VERSION ""

NS_ :

BS_:

BU_: VGW

BO_ 2566844158 ET1: 8 VGW
 SG_ EngCoolantTemp : 0|8@1+ (1,-40) [-40|210] "deg" Vector__XXX

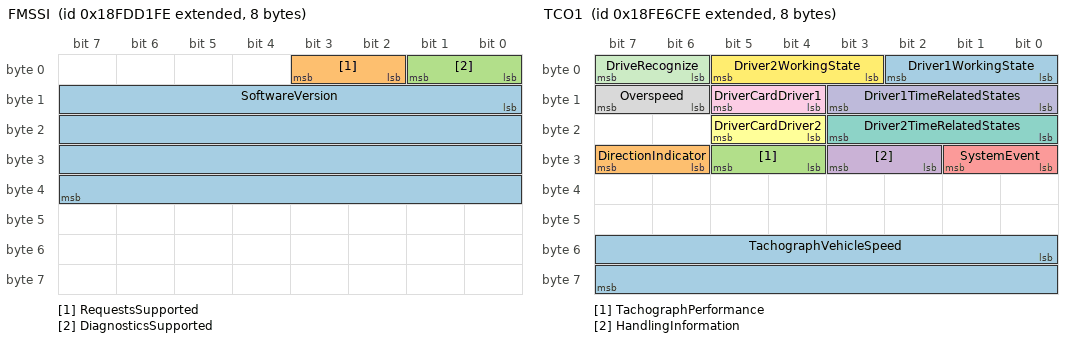
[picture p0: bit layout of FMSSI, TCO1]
BO_ 2566771198 FMSSI: 8 VGW
 SG_ SoftwareVersion : 8|32@1+ (1,0) [0|0] "" Vector__XXX
 SG_ RequestsSupported : 2|2@1+ (1,0) [0|3] "" Vector__XXX
 SG_ DiagnosticsSupported : 0|2@1+ (1,0) [0|3] "" Vector__XXX

BO_ 2566841854 HOURS: 8 VGW
 SG_ EngTotalHoursOfOperation : 0|32@1+ (0.5,0) [0|210554060.75] "hr" Vector__XXX

BO_ 2566843134 VW: 8 VGW
 SG_ AxleWeight : 8|16@1+ (0.5,0) [0|32127.5] "kg" Vector__XXX
 SG_ AxleLocation : 0|8@1+ (1,0) [0|255] "" Vector__XXX

BO_ 2566843646 VI: 255 VGW
 SG_ VehicleIdentificationNumber : 0|8@1+ (1,0) [0|255] "" Vector__XXX

BO_ 2566832638 VDHR: 8 VGW
 SG_ HghRslutionTotalVehicleDistance : 0|32@1+ (5,0) [0|21055406] "km" Vector__XXX

BO_ 2566810878 TCO1: 8 VGW
 SG_ TachographVehicleSpeed : 48|16@1+ (0.00390625,0) [0|250.996] "km/h" Vector__XXX
 SG_ DirectionIndicator : 30|2@1+ (1,0) [0|3] "" Vector__XXX
 SG_ TachographPerformance : 28|2@1+ (1,0) [0|3] "" Vector__XXX
 SG_ HandlingInformation : 26|2@1+ (1,0) [0|3] "" Vector__XXX
 SG_ SystemEvent : 24|2@1+ (1,0) [0|3] "" Vector__XXX
 SG_ DriverCardDriver2 : 20|2@1+ (1,0) [0|3] "" Vector__XXX
 SG_ Driver2TimeRelatedStates : 16|4@1+ (1,0) [0|15] "" Vector__XXX
 SG_ Overspeed : 14|2@1+ (1,0) [0|3] "" Vector__XXX
 SG_ DriverCardDriver1 : 12|2@1+ (1,0) [0|3] "" Vector__XXX
 SG_ Driver1TimeRelatedStates : 8|4@1+ (1,0) [0|15] "" Vector__XXX
 SG_ DriveRecognize : 6|2@1+ (1,0) [0|3] "" Vector__XXX
 SG_ Driver2WorkingState : 3|3@1+ (1,0) [0|7] "" Vector__XXX
 SG_ Driver1WorkingState : 0|3@1+ (1,0) [0|7] "" Vector__XXX

BO_ 2566832382 SERV: 8 VGW
 SG_ ServiceDistance : 8|16@1+ (5,-159365) [-159365|160640] "km" Vector__XXX

BO_ 2566842878 LFC: 8 VGW
 SG_ EngTotalFuelUsed : 32|32@1+ (0.5,0) [0|2105540607.5] "L" Vector__XXX

BO_ 2565866494 EEC2: 8 VGW
 SG_ AccelPedalPosition1 : 8|8@1+ (0.4,0) [0|100] "%" Vector__XXX

BO_ 2565866750 EEC1: 8 VGW
 SG_ EngSpeed : 24|16@1+ (0.125,0) [0|8031.875] "rpm" Vector__XXX

BO_ 2566847742 DD: 8 VGW
 SG_ FuelLevel : 8|8@1+ (0.4,0) [0|100] "%" Vector__XXX

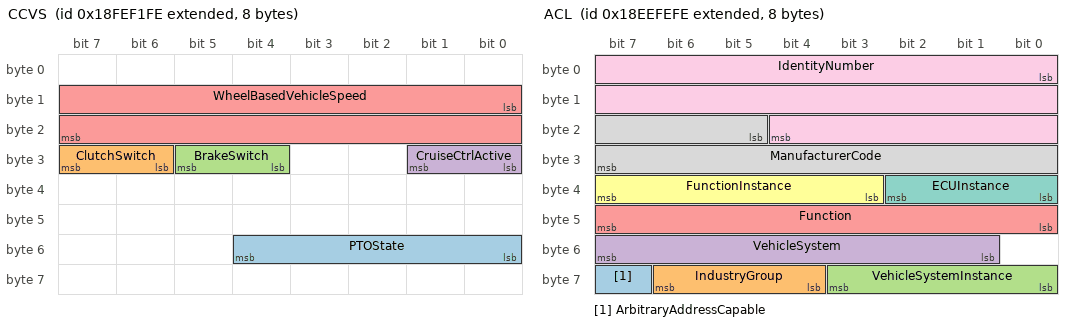
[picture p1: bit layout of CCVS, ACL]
BO_ 2566844926 CCVS: 8 VGW
 SG_ PTOState : 48|5@1+ (1,0) [0|31] "" Vector__XXX
 SG_ ClutchSwitch : 30|2@1+ (1,0) [0|3] "" Vector__XXX
 SG_ BrakeSwitch : 28|2@1+ (1,0) [0|3] "" Vector__XXX
 SG_ CruiseCtrlActive : 24|2@1+ (1,0) [0|3] "" Vector__XXX
 SG_ WheelBasedVehicleSpeed : 8|16@1+ (0.00390625,0) [0|255.99609375] "km/h" Vector__XXX

BO_ 2565799678 ACL: 8 VGW
 SG_ ArbitraryAddressCapable : 63|1@1+ (1,0) [0|1] "" Vector__XXX
 SG_ IndustryGroup : 60|3@1+ (1,0) [0|7] "" Vector__XXX
 SG_ VehicleSystemInstance : 56|4@1+ (1,0) [0|15] "" Vector__XXX
 SG_ VehicleSystem : 49|7@1+ (1,0) [0|127] "" Vector__XXX
 SG_ Function : 40|8@1+ (1,0) [0|255] "" Vector__XXX
 SG_ FunctionInstance : 35|5@1+ (1,0) [0|31] "" Vector__XXX
 SG_ ECUInstance : 32|3@1+ (1,0) [0|7] "" Vector__XXX
 SG_ ManufacturerCode : 21|11@1+ (1,0) [0|2047] "" Vector__XXX
 SG_ IdentityNumber : 0|21@1+ (1,0) [0|2097152] "" Vector__XXX

BO_ 2565603326 TPDT: 8 VGW
 SG_ SequenceNumber : 0|8@1+ (1,0) [0|252] "" Vector__XXX

BO_ 2565668862 TPCM: 8 VGW
 SG_ ConnectionAbortReason m255 : 8|8@1+ (1,0) [0|255] "" Vector__XXX
 SG_ NextPacketNumberToBeSent m17 : 16|8@1+ (1,0) [0|255] "" Vector__XXX
 SG_ NumberOfPacketsThatCanBeSent m17 : 8|8@1+ (1,0) [0|255] "" Vector__XXX
 SG_ PGNumber : 40|24@1+ (1,0) [0|16777200] "" Vector__XXX
 SG_ MaximumNumberOfPackets m16 : 32|8@1+ (1,0) [0|255] "" Vector__XXX
 SG_ TotalNumberOfPackets m32 : 24|8@1+ (1,0) [0|255] "" Vector__XXX
 SG_ TotalMessageSize m32 : 8|16@1+ (1,0) [0|64255] "counts" Vector__XXX
 SG_ ControlByte M : 0|8@1+ (1,0) [0|255] "" Vector__XXX

BO_ 2565537790 RQST: 3 Vector__XXX
 SG_ ParameterGroupNumber : 0|24@1+ (1,0) [0|16777215] "" Vector__XXX

BO_ 2565406462 ACKM: 8 VGW
 SG_ ParameterGroupNumber m3 : 40|24@1+ (1,0) [0|16777215] "" Vector__XXX
 SG_ GroupFunctionValue m3 : 8|8@1+ (1,0) [0|255] "" Vector__XXX
 SG_ ControlByte M : 0|8@1+ (1,0) [0|255] "" Vector__XXX

CM_ BU_ VGW "Vehicle Gateway";
CM_ BO_ 2566844158 "Engine Temperature 1";
CM_ SG_ 2566844158 EngCoolantTemp "Temperature of liquid found in engine cooling system.";
CM_ BO_ 2566771198 "FMS Standard Interface";
CM_ BO_ 2566841854 "Engine Hours, Revolutions";
CM_ SG_ 2566841854 EngTotalHoursOfOperation "Accumulated time of operation of engine.";
CM_ BO_ 2566843134 "Vehicle Weight";
CM_ SG_ 2566843134 AxleWeight "Total mass imposed by the tires on the road surface at the specified axle.";
CM_ SG_ 2566843134 AxleLocation "To identify to which of several similar devices (such as tires or fuel tanks) the information applies.";
CM_ BO_ 2566843646 "Vehicle Identification";
CM_ BO_ 2566832638 "High Resolution Vehicle Distance";
CM_ SG_ 2566832638 HghRslutionTotalVehicleDistance "Accumulated distance traveled by the vehicle during its operation.";
CM_ BO_ 2566810878 "Tachograph";
CM_ SG_ 2566810878 TachographVehicleSpeed "Speed of the vehicle registered by the tachograph.";
CM_ SG_ 2566810878 DirectionIndicator "Indicates the direction of the vehicle.";
CM_ SG_ 2566810878 HandlingInformation "Indicates that handling information is present.";
CM_ SG_ 2566810878 SystemEvent "Indicates that a tachograph event has occurred.";
CM_ SG_ 2566810878 Driver2TimeRelatedStates "Indicates if the driver approaches or exceeds working time limits (or other limits).";
CM_ SG_ 2566810878 Overspeed "Indicates whether the vehicle is exceeding the legal speed limit set in the tachograph.";
CM_ SG_ 2566810878 Driver1TimeRelatedStates "Indicates if the driver approaches or exceeds working time limits (or other limits).";
CM_ SG_ 2566810878 DriveRecognize "Indicates whether motion of the vehicle is detected or not.";
CM_ SG_ 2566810878 Driver2WorkingState "State of work of the driver.";
CM_ SG_ 2566810878 Driver1WorkingState "State of work of the driver.";
CM_ BO_ 2566832382 "Service Information";
CM_ SG_ 2566832382 ServiceDistance "The distance which can be traveled by the vehicle before the next service inspection is required.";
CM_ BO_ 2566842878 "Fuel Consumption (Liquid)";
CM_ SG_ 2566842878 EngTotalFuelUsed "Accumulated amount of fuel used during vehicle operation.";
CM_ BO_ 2565866494 "Electronic Engine Controller 2";
CM_ BO_ 2565866750 "Electronic Engine Controller 1";
CM_ BO_ 2566847742 "Dash Display";
CM_ SG_ 2566847742 FuelLevel "Ratio of volume of fuel to the total volume of fuel storage container.";
CM_ BO_ 2566844926 "Cruise Control/Vehicle Speed";
CM_ SG_ 2566844926 PTOState "This parameter is used to indicate the current state or mode of operation by the power takeoff (PTO) device.";
CM_ SG_ 2566844926 ClutchSwitch "Switch signal which indicates that the clutch pedal is being pressed.";
CM_ SG_ 2566844926 BrakeSwitch "Switch signal which indicates that the driver operated brake foot pedal is being pressed.";
CM_ SG_ 2566844926 CruiseCtrlActive "Cruise control is switched on.";
CM_ SG_ 2566844926 WheelBasedVehicleSpeed "Speed of the vehicle as calculated from wheel or tailshaft speed.";
CM_ BO_ 2565799678 "Address Claimed";
CM_ BO_ 2565603326 "Transport Protocol - Data Transfer";
CM_ BO_ 2565668862 "Transport Protocol - Connection Mgmt";
CM_ SG_ 2565668862 ConnectionAbortReason "Reason for connection abort message.";
CM_ SG_ 2565668862 NextPacketNumberToBeSent "Next Packet Number to be sent (TP.CM_CTS)";
CM_ SG_ 2565668862 NumberOfPacketsThatCanBeSent "Number of Packets that can be sent (TP.CM_CTS)";
CM_ SG_ 2565668862 MaximumNumberOfPackets "Maximum number of packets for RTS/CTS message.";
CM_ SG_ 2565668862 TotalNumberOfPackets "Total number of packets for BAM message.Total number of packets received for RTS/CTS message.Total number of packets for RTS/CTS message.";
CM_ SG_ 2565668862 TotalMessageSize "Total message size (in bytes) for BAM message.Total message size (in bytes) for RTS/CTS message.Total message size (in bytes) for RTS/CTS message.";
CM_ BO_ 2565537790 "Request";
CM_ SG_ 2565537790 ParameterGroupNumber "PGN which is requested by Request2 message";
CM_ BO_ 2565406462 "Acknowledgment Message";
CM_ SG_ 2565406462 ParameterGroupNumber "PGN which is requested by Request2 message";
CM_ SG_ 2565406462 GroupFunctionValue "Indicates the acknowledgement response.Indicates the acknowledgement response.Negative Acknowledgement Group Function valuePositive Acknowledgement Group Function value";
BA_DEF_ BO_  "VFrameFormat" ENUM  "StandardCAN","ExtendedCAN","reserved","J1939PG","vector_leerstring";
BA_DEF_ BO_  "GenMsgSendType" ENUM  "cyclic","reserved","cyclicIfActive","reserved","reserved","reserved","reserved","reserved","noMsgSendType","vector_leerstring";
BA_DEF_ BO_  "GenMsgCycleTime" INT 0 3600000;
BA_DEF_ BO_  "GenMsgRequestable" INT 0 1;
BA_DEF_ BU_  "NmStationAddress" INT 0 255;
BA_DEF_ BU_  "NmJ1939AAC" INT 0 1;
BA_DEF_ BU_  "NmJ1939IndustryGroup" INT 0 7;
BA_DEF_ BU_  "NmJ1939System" INT 0 127;
BA_DEF_ BU_  "NmJ1939SystemInstance" INT 0 15;
BA_DEF_ BU_  "NmJ1939Function" INT 0 255;
BA_DEF_ BU_  "NmJ1939FunctionInstance" INT 0 7;
BA_DEF_ BU_  "NmJ1939ECUInstance" INT 0 7;
BA_DEF_ BU_  "NmJ1939ManufacturerCode" INT 0 2047;
BA_DEF_ BU_  "NmJ1939IdentityNumber" INT 0 2097151;
BA_DEF_ BU_  "ECU" STRING ;
BA_DEF_  "ProtocolType" STRING ;
BA_DEF_  "LastModified" STRING ;
BA_DEF_  "BusType" STRING ;
BA_DEF_ SG_  "SigType" STRING ;
BA_DEF_ SG_  "SPN" INT 0 524287;
BA_DEF_DEF_  "VFrameFormat" "J1939PG";
BA_DEF_DEF_  "GenMsgSendType" "noMsgSendType";
BA_DEF_DEF_  "GenMsgCycleTime" 0;
BA_DEF_DEF_  "GenMsgRequestable" 1;
BA_DEF_DEF_  "NmStationAddress" 254;
BA_DEF_DEF_  "NmJ1939AAC" 0;
BA_DEF_DEF_  "NmJ1939IndustryGroup" 0;
BA_DEF_DEF_  "NmJ1939System" 0;
BA_DEF_DEF_  "NmJ1939SystemInstance" 0;
BA_DEF_DEF_  "NmJ1939Function" 0;
BA_DEF_DEF_  "NmJ1939FunctionInstance" 0;
BA_DEF_DEF_  "NmJ1939ECUInstance" 0;
BA_DEF_DEF_  "NmJ1939ManufacturerCode" 0;
BA_DEF_DEF_  "NmJ1939IdentityNumber" 0;
BA_DEF_DEF_  "ECU" "";
BA_DEF_DEF_  "ProtocolType" "";
BA_DEF_DEF_  "LastModified" "";
BA_DEF_DEF_  "BusType" "";
BA_DEF_DEF_  "SigType" "";
BA_DEF_DEF_  "SPN" 0;
BA_ "BusType" "CAN";
BA_ "ProtocolType" "J1939";
BA_ "LastModified" "2011-05-11";
BA_ "ECU" BU_ VGW "VGW";
BA_ "NmJ1939IdentityNumber" BU_ VGW 603241;
BA_ "NmJ1939ManufacturerCode" BU_ VGW 1861;
BA_ "NmJ1939Function" BU_ VGW 131;
BA_ "NmJ1939IndustryGroup" BU_ VGW 1;
BA_ "NmStationAddress" BU_ VGW 230;
BA_ "GenMsgSendType" BO_ 2566844158 0;
BA_ "GenMsgCycleTime" BO_ 2566844158 1000;
BA_ "GenMsgSendType" BO_ 2566771198 0;
BA_ "GenMsgCycleTime" BO_ 2566771198 10000;
BA_ "GenMsgSendType" BO_ 2566841854 0;
BA_ "GenMsgCycleTime" BO_ 2566841854 1000;
BA_ "GenMsgSendType" BO_ 2566843134 0;
BA_ "GenMsgCycleTime" BO_ 2566843134 1000;
BA_ "GenMsgSendType" BO_ 2566843646 0;
BA_ "GenMsgCycleTime" BO_ 2566843646 10000;
BA_ "GenMsgSendType" BO_ 2566832638 0;
BA_ "GenMsgCycleTime" BO_ 2566832638 1000;
BA_ "GenMsgSendType" BO_ 2566810878 0;
BA_ "GenMsgCycleTime" BO_ 2566810878 50;
BA_ "GenMsgSendType" BO_ 2566832382 0;
BA_ "GenMsgCycleTime" BO_ 2566832382 1000;
BA_ "GenMsgSendType" BO_ 2566842878 0;
BA_ "GenMsgCycleTime" BO_ 2566842878 1000;
BA_ "GenMsgSendType" BO_ 2565866494 0;
BA_ "GenMsgCycleTime" BO_ 2565866494 50;
BA_ "GenMsgSendType" BO_ 2565866750 0;
BA_ "GenMsgCycleTime" BO_ 2565866750 20;
BA_ "GenMsgSendType" BO_ 2566847742 0;
BA_ "GenMsgCycleTime" BO_ 2566847742 1000;
BA_ "GenMsgSendType" BO_ 2566844926 0;
BA_ "GenMsgCycleTime" BO_ 2566844926 100;
BA_ "GenMsgSendType" BO_ 2565799678 0;
BA_ "GenMsgSendType" BO_ 2565603326 0;
BA_ "GenMsgSendType" BO_ 2565668862 0;
BA_ "GenMsgSendType" BO_ 2565537790 0;
BA_ "GenMsgSendType" BO_ 2565406462 0;
BA_ "SigType" SG_ 2566844158 EngCoolantTemp "RANGE";
BA_ "SPN" SG_ 2566844158 EngCoolantTemp 110;
BA_ "SigType" SG_ 2566771198 RequestsSupported "DISCRETE";
BA_ "SigType" SG_ 2566771198 DiagnosticsSupported "DISCRETE";
BA_ "SigType" SG_ 2566841854 EngTotalHoursOfOperation "RANGE";
BA_ "SPN" SG_ 2566841854 EngTotalHoursOfOperation 247;
BA_ "SigType" SG_ 2566843134 AxleWeight "RANGE";
BA_ "SPN" SG_ 2566843134 AxleWeight 582;
BA_ "SigType" SG_ 2566843134 AxleLocation "RANGE";
BA_ "SPN" SG_ 2566843134 AxleLocation 928;
BA_ "SPN" SG_ 2566843646 VehicleIdentificationNumber 237;
BA_ "SigType" SG_ 2566843646 VehicleIdentificationNumber "STRING_DELIMITER";
BA_ "SigType" SG_ 2566832638 HghRslutionTotalVehicleDistance "RANGE";
BA_ "SPN" SG_ 2566832638 HghRslutionTotalVehicleDistance 917;
BA_ "SigType" SG_ 2566810878 TachographVehicleSpeed "RANGE";
BA_ "SPN" SG_ 2566810878 TachographVehicleSpeed 1624;
BA_ "SigType" SG_ 2566810878 DirectionIndicator "DISCRETE";
BA_ "SPN" SG_ 2566810878 DirectionIndicator 1619;
BA_ "SigType" SG_ 2566810878 TachographPerformance "DISCRETE";
BA_ "SPN" SG_ 2566810878 TachographPerformance 1620;
BA_ "SigType" SG_ 2566810878 HandlingInformation "DISCRETE";
BA_ "SPN" SG_ 2566810878 HandlingInformation 1621;
BA_ "SigType" SG_ 2566810878 SystemEvent "DISCRETE";
BA_ "SPN" SG_ 2566810878 SystemEvent 1622;
BA_ "SigType" SG_ 2566810878 DriverCardDriver2 "DISCRETE";
BA_ "SPN" SG_ 2566810878 DriverCardDriver2 1616;
BA_ "SigType" SG_ 2566810878 Driver2TimeRelatedStates "DISCRETE";
BA_ "SPN" SG_ 2566810878 Driver2TimeRelatedStates 1618;
BA_ "SigType" SG_ 2566810878 Overspeed "DISCRETE";
BA_ "SPN" SG_ 2566810878 Overspeed 1614;
BA_ "SigType" SG_ 2566810878 DriverCardDriver1 "DISCRETE";
BA_ "SPN" SG_ 2566810878 DriverCardDriver1 1615;
BA_ "SigType" SG_ 2566810878 Driver1TimeRelatedStates "DISCRETE";
BA_ "SPN" SG_ 2566810878 Driver1TimeRelatedStates 1617;
BA_ "SigType" SG_ 2566810878 DriveRecognize "DISCRETE";
BA_ "SPN" SG_ 2566810878 DriveRecognize 1611;
BA_ "SigType" SG_ 2566810878 Driver2WorkingState "DISCRETE";
BA_ "SPN" SG_ 2566810878 Driver2WorkingState 1613;
BA_ "SigType" SG_ 2566810878 Driver1WorkingState "DISCRETE";
BA_ "SPN" SG_ 2566810878 Driver1WorkingState 1612;
BA_ "SigType" SG_ 2566832382 ServiceDistance "RANGE";
BA_ "SPN" SG_ 2566832382 ServiceDistance 914;
BA_ "SigType" SG_ 2566842878 EngTotalFuelUsed "RANGE";
BA_ "SPN" SG_ 2566842878 EngTotalFuelUsed 250;
BA_ "SigType" SG_ 2565866494 AccelPedalPosition1 "RANGE";
BA_ "SPN" SG_ 2565866494 AccelPedalPosition1 91;
BA_ "SigType" SG_ 2565866750 EngSpeed "RANGE";
BA_ "SPN" SG_ 2565866750 EngSpeed 190;
BA_ "SigType" SG_ 2566847742 FuelLevel "RANGE";
BA_ "SPN" SG_ 2566847742 FuelLevel 96;
BA_ "SigType" SG_ 2566844926 PTOState "RANGE";
BA_ "SPN" SG_ 2566844926 PTOState 976;
BA_ "SigType" SG_ 2566844926 ClutchSwitch "DISCRETE";
BA_ "SPN" SG_ 2566844926 ClutchSwitch 598;
BA_ "SigType" SG_ 2566844926 BrakeSwitch "DISCRETE";
BA_ "SPN" SG_ 2566844926 BrakeSwitch 597;
BA_ "SigType" SG_ 2566844926 CruiseCtrlActive "DISCRETE";
BA_ "SPN" SG_ 2566844926 CruiseCtrlActive 595;
BA_ "SigType" SG_ 2566844926 WheelBasedVehicleSpeed "RANGE";
BA_ "SPN" SG_ 2566844926 WheelBasedVehicleSpeed 84;
BA_ "SigType" SG_ 2565603326 SequenceNumber "RANGE";
BA_ "SPN" SG_ 2565603326 SequenceNumber 2572;
BA_ "SigType" SG_ 2565668862 ConnectionAbortReason "RANGE";
BA_ "SPN" SG_ 2565668862 ConnectionAbortReason 2570;
BA_ "SigType" SG_ 2565668862 NextPacketNumberToBeSent "RANGE";
BA_ "SPN" SG_ 2565668862 NextPacketNumberToBeSent 2562;
BA_ "SigType" SG_ 2565668862 NumberOfPacketsThatCanBeSent "RANGE";
BA_ "SPN" SG_ 2565668862 NumberOfPacketsThatCanBeSent 2561;
BA_ "SigType" SG_ 2565668862 PGNumber "PGN";
BA_ "SigType" SG_ 2565668862 MaximumNumberOfPackets "RANGE";
BA_ "SPN" SG_ 2565668862 MaximumNumberOfPackets 2559;
BA_ "SigType" SG_ 2565668862 TotalNumberOfPackets "RANGE";
BA_ "SPN" SG_ 2565668862 TotalNumberOfPackets 2558;
BA_ "SigType" SG_ 2565668862 TotalMessageSize "RANGE";
BA_ "SPN" SG_ 2565668862 TotalMessageSize 2557;
BA_ "SigType" SG_ 2565668862 ControlByte "SPECIFIC";
BA_ "SPN" SG_ 2565668862 ControlByte 2556;
BA_ "SigType" SG_ 2565537790 ParameterGroupNumber "PGN";
BA_ "SPN" SG_ 2565537790 ParameterGroupNumber 2574;
BA_ "SigType" SG_ 2565406462 ParameterGroupNumber "PGN";
BA_ "SPN" SG_ 2565406462 ParameterGroupNumber 2574;
BA_ "SigType" SG_ 2565406462 GroupFunctionValue "RANGE";
BA_ "SPN" SG_ 2565406462 GroupFunctionValue 2542;
BA_ "SigType" SG_ 2565406462 ControlByte "SPECIFIC";
BA_ "SPN" SG_ 2565406462 ControlByte 2556;
VAL_ 2566771198 RequestsSupported 3 "Don't care" 2 "reserved" 1 "Request is supported" 0 "Request is not supported" ;
VAL_ 2566771198 DiagnosticsSupported 3 "Don't care" 2 "reserved" 1 "Diagnostics is supported" 0 "Diagnostics is not supported" ;
VAL_ 2566810878 DirectionIndicator 1 "Reverse" 0 "Forward" ;
VAL_ 2566810878 TachographPerformance 1 "PerformanceAnalysis" 0 "NormalPerformance" ;
VAL_ 2566810878 HandlingInformation 1 "HandlingInformation" 0 "NoHandlingInformation" ;
VAL_ 2566810878 SystemEvent 1 "TachographEvent" 0 "NoTachographEvent" ;
VAL_ 2566810878 DriverCardDriver2 1 "DriverCardPresent" 0 "DriverCardNotPresent" ;
VAL_ 2566810878 Driver2TimeRelatedStates 15 "NotAvailable" 14 "Error" 13 "Other" 7 "1100Reserved" 6 "Limit616HReached" 5 "Limit515MinBefore16H" 4 "Limit49HReached" 3 "Limit315MinBefore9H" 2 "Limit24½HReached" 1 "Limit115MinBefore4½H" 0 "Normal_NoLimitsReached" ;
VAL_ 2566810878 Overspeed 1 "Overspeed" 0 "NoOverspeed" ;
VAL_ 2566810878 DriverCardDriver1 1 "DriverCardPresent" 0 "DriverCardNotPresent" ;
VAL_ 2566810878 Driver1TimeRelatedStates 15 "NotAvailable" 14 "Error" 13 "Other" 7 "1100Reserved" 6 "Limit616HReached" 5 "Limit515MinBefore16H" 4 "Limit49HReached" 3 "Limit315MinBefore9H" 2 "Limit24½HReached" 1 "Limit115MinBefore4½H" 0 "Normal_NoLimitsReached" ;
VAL_ 2566810878 DriveRecognize 1 "VehicleMotionDetected" 0 "VehicleMotionNotDetected" ;
VAL_ 2566810878 Driver2WorkingState 7 "NotAvailable" 6 "Error" 4 "101Reserved" 3 "DriveBehindWheel" 2 "WrkLdngUnldingWorkingInAnOffice" 1 "DriverAvailableShortBreak" 0 "RestSleeping" ;
VAL_ 2566810878 Driver1WorkingState 7 "NotAvailable" 6 "Error" 4 "101Reserved" 3 "DriveBehindWheel" 2 "WrkLdngUnldingWorkingInAnOffice" 1 "DriverAvailableShortBreak" 0 "RestSleeping" ;
VAL_ 2565866494 AccelPedalPosition1 1 "SPN558" ;
VAL_ 2566844926 ClutchSwitch 1 "ClutchPedalDepressed" 0 "ClutchPedalReleased" ;
VAL_ 2566844926 BrakeSwitch 3 "NotAvailable" 2 "Error" 1 "BrakePedalDepressed" 0 "BrakePedalReleased" ;
VAL_ 2566844926 CruiseCtrlActive 1 "CruiseCtrlSwitchedOn" 0 "CruiseCtrlSwitchedOff" ;
VAL_ 2565668862 ControlByte 24 "EAbort" 23 "EEoMACK" 22 "EDPO" 21 "ECTS" 20 "ERTS" 3 "CannotRespond" 2 "AccessDenied" 1 "NACK" 0 "ACK" 255 "Abort" 32 "BAM" 19 "EoMA" 17 "CTS" 16 "RTS" ;
VAL_ 2565406462 ControlByte 24 "EAbort" 23 "EEoMACK" 22 "EDPO" 21 "ECTS" 20 "ERTS" 3 "CannotRespond" 2 "AccessDenied" 1 "NACK" 0 "ACK" 255 "Abort" 32 "BAM" 19 "EoMA" 17 "CTS" 16 "RTS" ;
